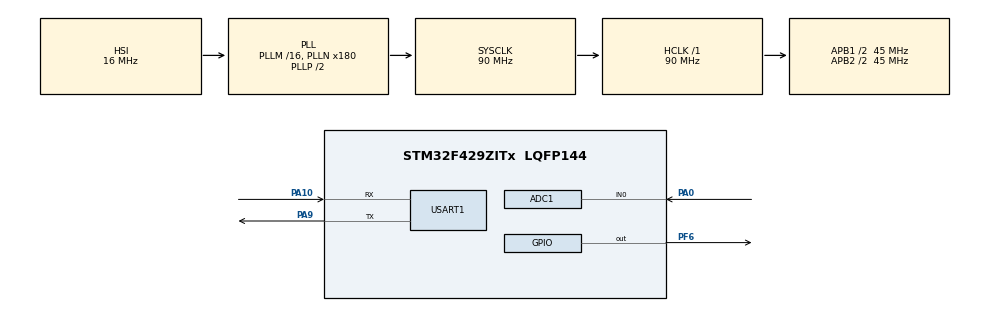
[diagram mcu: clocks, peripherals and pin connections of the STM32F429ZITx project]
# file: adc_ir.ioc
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ADC1.Channel-1\#ChannelRegularConversion=ADC_CHANNEL_0
ADC1.NbrOfConversionFlag=1
ADC1.Rank-1\#ChannelRegularConversion=1
ADC1.SamplingTime-1\#ChannelRegularConversion=ADC_SAMPLETIME_3CYCLES
ADC1.master=1
Mcu.Family=STM32F4
Mcu.Name=STM32F429ZITx
Mcu.Package=LQFP144
NVIC.ADC_IRQn=true\:0\:0\:false\:false\:true\:true\:true
NVIC.PriorityGroup=NVIC_PRIORITYGROUP_4
PA0/WKUP.Signal=ADCx_IN0
PA10.Mode=Asynchronous
PA10.Signal=USART1_RX
PA9.Mode=Asynchronous
PA9.Signal=USART1_TX
PF6.Signal=GPIO_Output
ProjectManager.HeapSize=0x200
ProjectManager.StackSize=0x400
ProjectManager.TargetToolchain=MDK-ARM V5
RCC.48MHZClocksFreq_Value=45000000
RCC.AHBFreq_Value=90000000
RCC.APB1CLKDivider=RCC_HCLK_DIV2
RCC.APB1Freq_Value=45000000
RCC.APB1TimFreq_Value=90000000
RCC.APB2CLKDivider=RCC_HCLK_DIV2
RCC.APB2Freq_Value=45000000
RCC.APB2TimFreq_Value=90000000
RCC.CortexFreq_Value=90000000
RCC.HCLKFreq_Value=90000000
RCC.HSE_VALUE=25000000
RCC.HSI_VALUE=16000000
RCC.PLLN=180
RCC.SYSCLKFreq_VALUE=90000000
RCC.SYSCLKSource=RCC_SYSCLKSOURCE_PLLCLK
RCC.VCOOutputFreq_Value=180000000
SH.ADCx_IN0.0=ADC1_IN0,IN0
USART1.VirtualMode=VM_ASYNC
board=custom

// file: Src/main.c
/* USER CODE BEGIN Header */
/**
  ******************************************************************************
  * @file           : main.c
  * @brief          : Main program body
  ******************************************************************************
  * @attention
  *
  * <h2><center>&copy; Copyright (c) 2020 STMicroelectronics.
  * All rights reserved.</center></h2>
  *
  * This software component is licensed by ST under BSD 3-Clause license,
  * the "License"; You may not use this file except in compliance with the
  * License. You may obtain a copy of the License at:
  *                        opensource.org/licenses/BSD-3-Clause
  *
  ******************************************************************************
  */
/* USER CODE END Header */

#include "main.h"

/* USER CODE BEGIN Includes */
#include <string.h>
#include <stdio.h>
/* USER CODE END Includes */

ADC_HandleTypeDef hadc1;

UART_HandleTypeDef huart1;

void SystemClock_Config(void);
static void MX_GPIO_Init(void);
static void MX_ADC1_Init(void);
static void MX_USART1_UART_Init(void);
/* USER CODE BEGIN PFP */
void HAL_ADC_ConvtCpltCallback (ADC_HandleTypeDef *hadc);
/* USER CODE END PFP */

/* USER CODE BEGIN 0 */
uint32_t value=0;
uint8_t icFlag = 0;
char uartBuf[100];
/* USER CODE END 0 */

int main(void)
{

  /* MCU Configuration--------------------------------------------------------*/

  /* Reset of all peripherals, Initializes the Flash interface and the Systick. */
                                                                                                                                                                             HAL_Init();

  /* Configure the system clock */
  SystemClock_Config();

  /* Initialize all configured peripherals */
  MX_GPIO_Init();
  MX_ADC1_Init();
  MX_USART1_UART_Init();
  /* USER CODE BEGIN 2 */
float dist1;
  /* USER CODE END 2 */

  /* Infinite loop */
  while (1)
  {

    /* USER CODE BEGIN 3 */
//		HAL_GPIO_WritePin(GPIOF, GPIO_PIN_6, GPIO_PIN_RESET);
	//	HAL_GPIO_WritePin(GPIOF, GPIO_PIN_6, GPIO_PIN_SET);
				HAL_ADC_Start_IT (&hadc1);  // start ADC in interrupt mode
	dist1 = value + 0.0f;
//		dist1 = 5461/(value -17 + 0.0f) -2;

		sprintf(uartBuf, "Distance (cm)  = %.1f\r\n", dist1);
		HAL_UART_Transmit(&huart1, (uint8_t *)uartBuf, strlen(uartBuf), 100);

		HAL_Delay(1000);

  }
  /* USER CODE END 3 */
}

void SystemClock_Config(void)
{
  RCC_OscInitTypeDef RCC_OscInitStruct = {0};
  RCC_ClkInitTypeDef RCC_ClkInitStruct = {0};

  /** Configure the main internal regulator output voltage
  */
  __HAL_RCC_PWR_CLK_ENABLE();
  __HAL_PWR_VOLTAGESCALING_CONFIG(PWR_REGULATOR_VOLTAGE_SCALE3);
  /** Initializes the CPU, AHB and APB busses clocks
  */
  RCC_OscInitStruct.OscillatorType = RCC_OSCILLATORTYPE_HSI;
  RCC_OscInitStruct.HSIState = RCC_HSI_ON;
  RCC_OscInitStruct.HSICalibrationValue = RCC_HSICALIBRATION_DEFAULT;
  RCC_OscInitStruct.PLL.PLLState = RCC_PLL_ON;
  RCC_OscInitStruct.PLL.PLLSource = RCC_PLLSOURCE_HSI;
  RCC_OscInitStruct.PLL.PLLM = 16;
  RCC_OscInitStruct.PLL.PLLN = 180;
  RCC_OscInitStruct.PLL.PLLP = RCC_PLLP_DIV2;
  RCC_OscInitStruct.PLL.PLLQ = 4;
  if (HAL_RCC_OscConfig(&RCC_OscInitStruct) != HAL_OK)
  {
    Error_Handler();
  }
  /** Activate the Over-Drive mode
  */
  if (HAL_PWREx_EnableOverDrive() != HAL_OK)
  {
    Error_Handler();
  }
  /** Initializes the CPU, AHB and APB busses clocks
  */
  RCC_ClkInitStruct.ClockType = RCC_CLOCKTYPE_HCLK|RCC_CLOCKTYPE_SYSCLK
                              |RCC_CLOCKTYPE_PCLK1|RCC_CLOCKTYPE_PCLK2;
  RCC_ClkInitStruct.SYSCLKSource = RCC_SYSCLKSOURCE_PLLCLK;
  RCC_ClkInitStruct.AHBCLKDivider = RCC_SYSCLK_DIV1;
  RCC_ClkInitStruct.APB1CLKDivider = RCC_HCLK_DIV2;
  RCC_ClkInitStruct.APB2CLKDivider = RCC_HCLK_DIV2;

  if (HAL_RCC_ClockConfig(&RCC_ClkInitStruct, FLASH_LATENCY_2) != HAL_OK)
  {
    Error_Handler();
  }
}

static void MX_ADC1_Init(void)
{

  ADC_ChannelConfTypeDef sConfig = {0};

  /** Configure the global features of the ADC (Clock, Resolution, Data Alignment and number of conversion)
  */
  hadc1.Instance = ADC1;
  hadc1.Init.ClockPrescaler = ADC_CLOCK_SYNC_PCLK_DIV2;
  hadc1.Init.Resolution = ADC_RESOLUTION_12B;
  hadc1.Init.ScanConvMode = DISABLE;
  hadc1.Init.ContinuousConvMode = DISABLE;
  hadc1.Init.DiscontinuousConvMode = DISABLE;
  hadc1.Init.ExternalTrigConvEdge = ADC_EXTERNALTRIGCONVEDGE_NONE;
  hadc1.Init.ExternalTrigConv = ADC_SOFTWARE_START;
  hadc1.Init.DataAlign = ADC_DATAALIGN_RIGHT;
  hadc1.Init.NbrOfConversion = 1;
  hadc1.Init.DMAContinuousRequests = DISABLE;
  hadc1.Init.EOCSelection = ADC_EOC_SINGLE_CONV;
  if (HAL_ADC_Init(&hadc1) != HAL_OK)
  {
    Error_Handler();
  }
  /** Configure for the selected ADC regular channel its corresponding rank in the sequencer and its sample time.
  */
  sConfig.Channel = ADC_CHANNEL_0;
  sConfig.Rank = 1;
  sConfig.SamplingTime = ADC_SAMPLETIME_3CYCLES;
  if (HAL_ADC_ConfigChannel(&hadc1, &sConfig) != HAL_OK)
  {
    Error_Handler();
  }

}

static void MX_USART1_UART_Init(void)
{

  huart1.Instance = USART1;
  huart1.Init.BaudRate = 115200;
  huart1.Init.WordLength = UART_WORDLENGTH_8B;
  huart1.Init.StopBits = UART_STOPBITS_1;
  huart1.Init.Parity = UART_PARITY_NONE;
  huart1.Init.Mode = UART_MODE_TX_RX;
  huart1.Init.HwFlowCtl = UART_HWCONTROL_NONE;
  huart1.Init.OverSampling = UART_OVERSAMPLING_16;
  if (HAL_UART_Init(&huart1) != HAL_OK)
  {
    Error_Handler();
  }

}

static void MX_GPIO_Init(void)
{
  GPIO_InitTypeDef GPIO_InitStruct = {0};

  /* GPIO Ports Clock Enable */
  __HAL_RCC_GPIOF_CLK_ENABLE();
  __HAL_RCC_GPIOA_CLK_ENABLE();

  /*Configure GPIO pin Output Level */
  HAL_GPIO_WritePin(GPIOF, GPIO_PIN_6, GPIO_PIN_RESET);

  /*Configure GPIO pin : PF6 */
  GPIO_InitStruct.Pin = GPIO_PIN_6;
  GPIO_InitStruct.Mode = GPIO_MODE_OUTPUT_PP;
  GPIO_InitStruct.Pull = GPIO_NOPULL;
  GPIO_InitStruct.Speed = GPIO_SPEED_FREQ_LOW;
  HAL_GPIO_Init(GPIOF, &GPIO_InitStruct);

}

/* USER CODE BEGIN 4 */
void HAL_ADC_ConvtCpltCallback (ADC_HandleTypeDef *hadc)
{
  value = HAL_ADC_GetValue (&hadc1);  // read the value of ADC
//	icFlag = 1;
}
/* USER CODE END 4 */

void Error_Handler(void)
{
}

/************************ (C) COPYRIGHT STMicroelectronics *****END OF FILE****/
